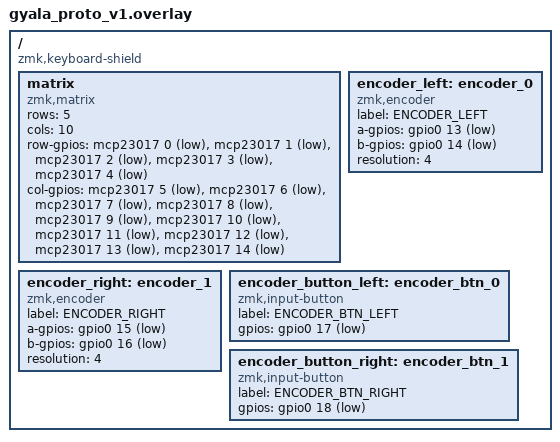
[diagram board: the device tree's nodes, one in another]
/ {
    compatible = "zmk,keyboard-shield";

    matrix {
        compatible = "zmk,matrix";
        rows = <5>;
        cols = <10>;
        row-gpios = <&mcp23017 0 GPIO_ACTIVE_LOW>, <&mcp23017 1 GPIO_ACTIVE_LOW>, <&mcp23017 2 GPIO_ACTIVE_LOW>,
                    <&mcp23017 3 GPIO_ACTIVE_LOW>, <&mcp23017 4 GPIO_ACTIVE_LOW>;
        col-gpios = <&mcp23017 5 GPIO_ACTIVE_LOW>, <&mcp23017 6 GPIO_ACTIVE_LOW>, <&mcp23017 7 GPIO_ACTIVE_LOW>,
                    <&mcp23017 8 GPIO_ACTIVE_LOW>, <&mcp23017 9 GPIO_ACTIVE_LOW>, <&mcp23017 10 GPIO_ACTIVE_LOW>,
                    <&mcp23017 11 GPIO_ACTIVE_LOW>, <&mcp23017 12 GPIO_ACTIVE_LOW>, <&mcp23017 13 GPIO_ACTIVE_LOW>,
                    <&mcp23017 14 GPIO_ACTIVE_LOW>;
    };

    encoder_left: encoder_0 {
        compatible = "zmk,encoder";
        label = "ENCODER_LEFT";
        a-gpios = <&gpio0 13 GPIO_ACTIVE_LOW>;
        b-gpios = <&gpio0 14 GPIO_ACTIVE_LOW>;
        resolution = <4>;
    };

    encoder_right: encoder_1 {
        compatible = "zmk,encoder";
        label = "ENCODER_RIGHT";
        a-gpios = <&gpio0 15 GPIO_ACTIVE_LOW>;
        b-gpios = <&gpio0 16 GPIO_ACTIVE_LOW>;
        resolution = <4>;
    };

    encoder_button_left: encoder_btn_0 {
        compatible = "zmk,input-button";
        label = "ENCODER_BTN_LEFT";
        gpios = <&gpio0 17 GPIO_ACTIVE_LOW>;
    };

    encoder_button_right: encoder_btn_1 {
        compatible = "zmk,input-button";
        label = "ENCODER_BTN_RIGHT";
        gpios = <&gpio0 18 GPIO_ACTIVE_LOW>;
    };
};
